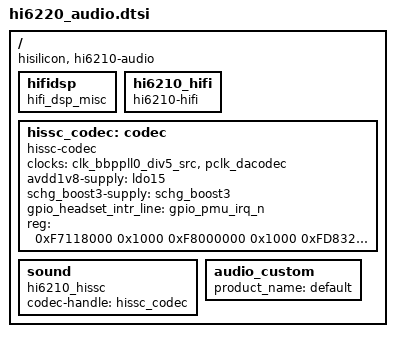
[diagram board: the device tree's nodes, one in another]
/*
 *  Copyright (C) 2013 Hisilicon Ltd.
 *
 *  This program is free software; you can redistribute it and/or modify
 *  it under the terms of the GNU General Public License version 2 as
 *  publishhed by the Free Software Foundation.
 */

/ {
   	compatible = "hisilicon, hi6210-audio";

	hifidsp {
		compatible = "hifi_dsp_misc";
		status = "ok";
	};

	hi6210_hifi {
		compatible = "hi6210-hifi";
		status = "ok";
	};

	/*hi6553 codec驱动*/
    hissc_codec:codec {
    	compatible = "hissc-codec";
		/*codec时钟		49.15M工作时钟	接口时钟*/
		clocks = <&clk_bbppll0_div5_src &pclk_dacodec>;
		/*电源		codec工作电源ldo15*/
		avdd1v8-supply = <&ldo15>;
		/*电源		scharge上给classd供电*/
		schg_boost3-supply = <&schg_boost3>;/* classd supply */
		/*中断		与pmu共中断线*/
        gpio_headset_intr_line = <&gpio_pmu_irq_n>;/*GPIO_1_6*/
		/*寄存器*/
		reg = <0xF7118000 0x1000	 /* soc codec*/
		       0xF8000000 0x1000     /* pmussi   */
		       0xFD832000 0x1000 	 /* hkadc    */
		       0xF7030000 0x1000>;   /* psctrl  */
        status = "ok";
    };

	sound {
		compatible = "hi6210_hissc";
		codec-handle = <&hissc_codec>;
		status = "ok";
	};

	audio_custom {
		product_name = "default";
		status = "ok";
	};
};
